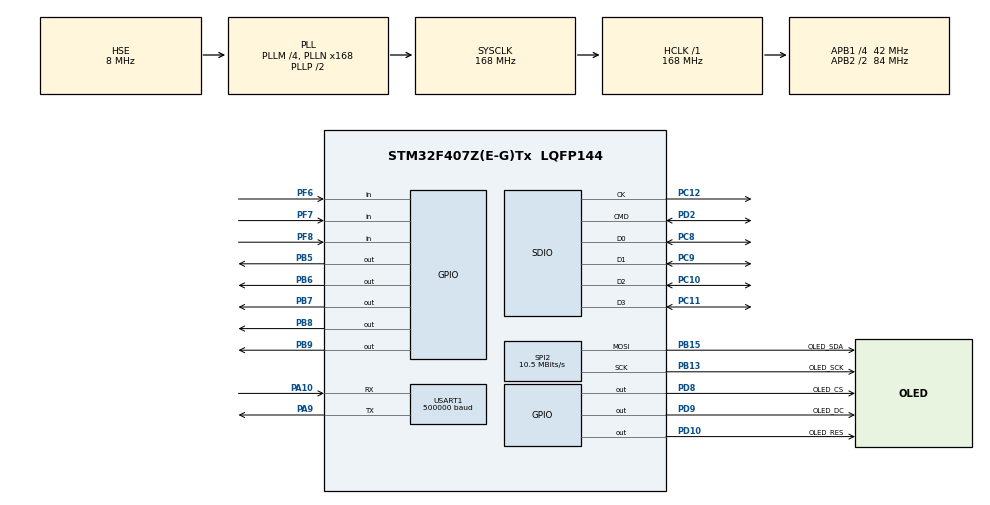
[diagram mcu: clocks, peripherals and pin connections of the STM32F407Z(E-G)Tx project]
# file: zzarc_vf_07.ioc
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Dma.Request0=SPI2_TX
Dma.Request1=SDIO
Dma.Request2=USART1_RX
Dma.Request3=USART1_TX
Dma.SDIO.1.Direction=DMA_PERIPH_TO_MEMORY
Dma.SDIO.1.FIFOMode=DMA_FIFOMODE_ENABLE
Dma.SDIO.1.FIFOThreshold=DMA_FIFO_THRESHOLD_FULL
Dma.SDIO.1.Instance=DMA2_Stream3
Dma.SDIO.1.MemBurst=DMA_MBURST_INC4
Dma.SDIO.1.MemDataAlignment=DMA_MDATAALIGN_WORD
Dma.SDIO.1.MemInc=DMA_MINC_ENABLE
Dma.SDIO.1.Mode=DMA_PFCTRL
Dma.SDIO.1.PeriphBurst=DMA_PBURST_INC4
Dma.SDIO.1.PeriphDataAlignment=DMA_PDATAALIGN_WORD
Dma.SDIO.1.PeriphInc=DMA_PINC_DISABLE
Dma.SDIO.1.Priority=DMA_PRIORITY_LOW
Dma.SPI2_TX.0.Direction=DMA_MEMORY_TO_PERIPH
Dma.SPI2_TX.0.FIFOMode=DMA_FIFOMODE_DISABLE
Dma.SPI2_TX.0.Instance=DMA1_Stream4
Dma.SPI2_TX.0.MemDataAlignment=DMA_MDATAALIGN_BYTE
Dma.SPI2_TX.0.MemInc=DMA_MINC_ENABLE
Dma.SPI2_TX.0.Mode=DMA_NORMAL
Dma.SPI2_TX.0.PeriphDataAlignment=DMA_PDATAALIGN_BYTE
Dma.SPI2_TX.0.PeriphInc=DMA_PINC_DISABLE
Dma.SPI2_TX.0.Priority=DMA_PRIORITY_MEDIUM
Dma.USART1_RX.2.Direction=DMA_PERIPH_TO_MEMORY
Dma.USART1_RX.2.FIFOMode=DMA_FIFOMODE_DISABLE
Dma.USART1_RX.2.Instance=DMA2_Stream2
Dma.USART1_RX.2.MemDataAlignment=DMA_MDATAALIGN_BYTE
Dma.USART1_RX.2.MemInc=DMA_MINC_ENABLE
Dma.USART1_RX.2.Mode=DMA_CIRCULAR
Dma.USART1_RX.2.PeriphDataAlignment=DMA_PDATAALIGN_BYTE
Dma.USART1_RX.2.PeriphInc=DMA_PINC_DISABLE
Dma.USART1_RX.2.Priority=DMA_PRIORITY_MEDIUM
Dma.USART1_TX.3.Direction=DMA_MEMORY_TO_PERIPH
Dma.USART1_TX.3.FIFOMode=DMA_FIFOMODE_DISABLE
Dma.USART1_TX.3.Instance=DMA2_Stream7
Dma.USART1_TX.3.MemDataAlignment=DMA_MDATAALIGN_BYTE
Dma.USART1_TX.3.MemInc=DMA_MINC_ENABLE
Dma.USART1_TX.3.Mode=DMA_NORMAL
Dma.USART1_TX.3.PeriphDataAlignment=DMA_PDATAALIGN_BYTE
Dma.USART1_TX.3.PeriphInc=DMA_PINC_DISABLE
Dma.USART1_TX.3.Priority=DMA_PRIORITY_MEDIUM
FATFS.USE_DMA_CODE_SD=1
FATFS._CODE_PAGE=936
Mcu.Family=STM32F4
Mcu.Name=STM32F407Z(E-G)Tx
Mcu.Package=LQFP144
NVIC.DMA1_Stream4_IRQn=true\:0\:0\:false\:false\:true\:false\:true\:true
NVIC.DMA2_Stream2_IRQn=true\:0\:0\:false\:false\:true\:false\:true\:true
NVIC.DMA2_Stream3_IRQn=true\:0\:0\:false\:false\:true\:false\:true\:true
NVIC.DMA2_Stream7_IRQn=true\:0\:0\:false\:false\:true\:false\:true\:true
NVIC.PriorityGroup=NVIC_PRIORITYGROUP_4
NVIC.TIM8_TRG_COM_TIM14_IRQn=true\:0\:0\:false\:false\:true\:true\:true\:true
NVIC.USART1_IRQn=true\:0\:0\:false\:false\:true\:true\:true\:true
PA10.GPIO_PuPd=GPIO_PULLUP
PA10.Mode=Asynchronous
PA10.Signal=USART1_RX
PA13.Mode=Serial_Wire
PA13.Signal=SYS_JTMS-SWDIO
PA14.Mode=Serial_Wire
PA14.Signal=SYS_JTCK-SWCLK
PA9.GPIO_PuPd=GPIO_PULLUP
PA9.Mode=Asynchronous
PA9.Signal=USART1_TX
PB13.GPIO_Label=OLED_SCK
PB13.GPIO_PuPd=GPIO_PULLUP
PB13.Mode=TX_Only_Simplex_Unidirect_Master
PB13.Signal=SPI2_SCK
PB15.GPIO_Label=OLED_SDA
PB15.GPIO_PuPd=GPIO_PULLUP
PB15.Mode=TX_Only_Simplex_Unidirect_Master
PB15.Signal=SPI2_MOSI
PB5.GPIO_PuPd=GPIO_PULLUP
PB5.Signal=GPIO_Output
PB6.GPIO_PuPd=GPIO_PULLUP
PB6.Signal=GPIO_Output
PB7.GPIO_PuPd=GPIO_PULLUP
PB7.Signal=GPIO_Output
PB8.GPIO_PuPd=GPIO_PULLUP
PB8.GPIO_Speed=GPIO_SPEED_FREQ_VERY_HIGH
PB8.Signal=GPIO_Output
PB9.GPIO_PuPd=GPIO_PULLUP
PB9.GPIO_Speed=GPIO_SPEED_FREQ_VERY_HIGH
PB9.PinState=GPIO_PIN_RESET
PB9.Signal=GPIO_Output
PC10.Mode=SD_4_bits_Wide_bus
PC10.Signal=SDIO_D2
PC11.Mode=SD_4_bits_Wide_bus
PC11.Signal=SDIO_D3
PC12.Mode=SD_4_bits_Wide_bus
PC12.Signal=SDIO_CK
PC8.Mode=SD_4_bits_Wide_bus
PC8.Signal=SDIO_D0
PC9.Mode=SD_4_bits_Wide_bus
PC9.Signal=SDIO_D1
PD10.GPIO_Label=OLED_RES
PD10.GPIO_PuPd=GPIO_PULLUP
PD10.Signal=GPIO_Output
PD2.Mode=SD_4_bits_Wide_bus
PD2.Signal=SDIO_CMD
PD8.GPIO_Label=OLED_CS
PD8.GPIO_PuPd=GPIO_PULLUP
PD8.Signal=GPIO_Output
PD9.GPIO_Label=OLED_DC
PD9.GPIO_PuPd=GPIO_PULLUP
PD9.Signal=GPIO_Output
PF6.GPIO_PuPd=GPIO_PULLUP
PF6.Signal=GPIO_Input
PF7.GPIO_PuPd=GPIO_PULLUP
PF7.Signal=GPIO_Input
PF8.GPIO_PuPd=GPIO_PULLUP
PF8.Signal=GPIO_Input
PH0-OSC_IN.Mode=HSE-External-Oscillator
PH0-OSC_IN.Signal=RCC_OSC_IN
PH1-OSC_OUT.Mode=HSE-External-Oscillator
PH1-OSC_OUT.Signal=RCC_OSC_OUT
ProjectManager.HeapSize=0x2000
ProjectManager.StackSize=0x1000
ProjectManager.TargetToolchain=MDK-ARM V5.32
RCC.48MHZClocksFreq_Value=48000000
RCC.AHBFreq_Value=168000000
RCC.APB1CLKDivider=RCC_HCLK_DIV4
RCC.APB1Freq_Value=42000000
RCC.APB1TimFreq_Value=84000000
RCC.APB2CLKDivider=RCC_HCLK_DIV2
RCC.APB2Freq_Value=84000000
RCC.APB2TimFreq_Value=168000000
RCC.CortexFreq_Value=168000000
RCC.HCLKFreq_Value=168000000
RCC.HSE_Timout=1000
RCC.HSE_VALUE=8000000
RCC.HSI_VALUE=16000000
RCC.LSE_VALUE=32768
RCC.PLLM=4
RCC.PLLN=168
RCC.PLLQ=7
RCC.PLLSourceVirtual=RCC_PLLSOURCE_HSE
RCC.SYSCLKFreq_VALUE=168000000
RCC.SYSCLKSource=RCC_SYSCLKSOURCE_PLLCLK
RCC.VCOOutputFreq_Value=336000000
SPI2.BaudRatePrescaler=SPI_BAUDRATEPRESCALER_4
SPI2.CalculateBaudRate=10.5 MBits/s
SPI2.Direction=SPI_DIRECTION_2LINES
SPI2.Mode=SPI_MODE_MASTER
SPI2.VirtualType=VM_MASTER
TIM14.AutoReloadPreload=TIM_AUTORELOAD_PRELOAD_ENABLE
TIM14.Period=9
TIM14.Prescaler=16799
USART1.BaudRate=500000
USART1.VirtualMode=VM_ASYNC
VP_FATFS_VS_SDIO.Mode=SDIO
VP_TIM14_VS_ClockSourceINT.Mode=Enable_Timer
board=custom

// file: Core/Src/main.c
/* USER CODE BEGIN Header */
/**
  ******************************************************************************
  * @file           : main.c
  * @brief          : Main program body
  ******************************************************************************
  * @attention
  *
  * Copyright (c) 2025 STMicroelectronics.
  * All rights reserved.
  *
  * This software is licensed under terms that can be found in the LICENSE file
  * in the root directory of this software component.
  * If no LICENSE file comes with this software, it is provided AS-IS.
  *
  ******************************************************************************
  */
/* USER CODE END Header */
#include "main.h"
#include "dma.h"
#include "fatfs.h"
#include "sdio.h"
#include "spi.h"
#include "tim.h"
#include "usart.h"
#include "gpio.h"

/* USER CODE BEGIN Includes */
#include "system_bsp.h"

#include "OLED_UI.h"
#include "OLED_UI_MenuData.h"

#include "file_operate.h"
/* USER CODE END Includes */

void SystemClock_Config(void);

int main(void)
{

  /* MCU Configuration--------------------------------------------------------*/

  /* Reset of all peripherals, Initializes the Flash interface and the Systick. */
  HAL_Init();

  /* Configure the system clock */
  SystemClock_Config();

  /* Initialize all configured peripherals */
  MX_GPIO_Init();
  MX_DMA_Init();
  MX_SPI2_Init();
  MX_TIM14_Init();
  MX_SDIO_SD_Init();
  MX_FATFS_Init();
  MX_USART1_UART_Init();
  /* USER CODE BEGIN 2 */
	system_bsp_init();
  /* USER CODE END 2 */

  /* Infinite loop */
  /* USER CODE BEGIN WHILE */
	system_bsp_test_loop();

  while (1)
  {
    /* USER CODE END WHILE */

  }
}

void SystemClock_Config(void)
{
  RCC_OscInitTypeDef RCC_OscInitStruct = {0};
  RCC_ClkInitTypeDef RCC_ClkInitStruct = {0};

  /** Configure the main internal regulator output voltage
  */
  __HAL_RCC_PWR_CLK_ENABLE();
  __HAL_PWR_VOLTAGESCALING_CONFIG(PWR_REGULATOR_VOLTAGE_SCALE1);

  /** Initializes the RCC Oscillators according to the specified parameters
  * in the RCC_OscInitTypeDef structure.
  */
  RCC_OscInitStruct.OscillatorType = RCC_OSCILLATORTYPE_HSE;
  RCC_OscInitStruct.HSEState = RCC_HSE_ON;
  RCC_OscInitStruct.PLL.PLLState = RCC_PLL_ON;
  RCC_OscInitStruct.PLL.PLLSource = RCC_PLLSOURCE_HSE;
  RCC_OscInitStruct.PLL.PLLM = 4;
  RCC_OscInitStruct.PLL.PLLN = 168;
  RCC_OscInitStruct.PLL.PLLP = RCC_PLLP_DIV2;
  RCC_OscInitStruct.PLL.PLLQ = 7;
  if (HAL_RCC_OscConfig(&RCC_OscInitStruct) != HAL_OK)
  {
    Error_Handler();
  }

  /** Initializes the CPU, AHB and APB buses clocks
  */
  RCC_ClkInitStruct.ClockType = RCC_CLOCKTYPE_HCLK|RCC_CLOCKTYPE_SYSCLK
                              |RCC_CLOCKTYPE_PCLK1|RCC_CLOCKTYPE_PCLK2;
  RCC_ClkInitStruct.SYSCLKSource = RCC_SYSCLKSOURCE_PLLCLK;
  RCC_ClkInitStruct.AHBCLKDivider = RCC_SYSCLK_DIV1;
  RCC_ClkInitStruct.APB1CLKDivider = RCC_HCLK_DIV4;
  RCC_ClkInitStruct.APB2CLKDivider = RCC_HCLK_DIV2;

  if (HAL_RCC_ClockConfig(&RCC_ClkInitStruct, FLASH_LATENCY_5) != HAL_OK)
  {
    Error_Handler();
  }
}

void Error_Handler(void)
{
  __disable_irq();
  while (1)
  {
  }
}
